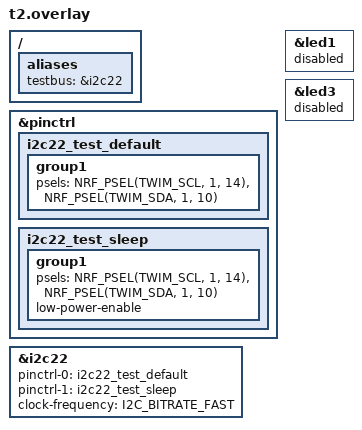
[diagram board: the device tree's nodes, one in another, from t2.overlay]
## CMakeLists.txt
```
cmake_minimum_required(VERSION 3.20.0)

find_package(Zephyr REQUIRED HINTS $ENV{ZEPHYR_BASE})
project(pin_assignment)

target_sources(app PRIVATE src/main.c)
```

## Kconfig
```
config TEST_LABEL
	string "Name of this test case, printed at startup"
	default "T1 baseline — SCL P1.11 (clock pin), SDA P1.10, both on P1"

config TEST_EXPECT_PASS
	bool "This case is expected to communicate successfully"
	default y
	help
	  Set n for the negative controls. The firmware compares the actual
	  result against this and shouts if they disagree — a rule you cannot
	  make fail is a rule you have not tested.

source "Kconfig.zephyr"
```

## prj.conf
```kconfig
CONFIG_I2C=y

# The I2C driver logs its own errors at this level, which is noise on the
# negative controls where errors are the expected result.
CONFIG_I2C_LOG_LEVEL_ERR=y
```

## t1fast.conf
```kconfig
CONFIG_TEST_LABEL="T1-fast — SCL P1.11 (clock pin), SDA P1.10, 1 MHz — control"
CONFIG_TEST_EXPECT_PASS=y
```

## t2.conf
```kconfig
CONFIG_TEST_LABEL="T2 negative — SCL P1.14 (NOT a clock pin), SDA P1.10"
CONFIG_TEST_EXPECT_PASS=n
```

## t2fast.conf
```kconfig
CONFIG_TEST_LABEL="T2-fast — SCL P1.14 (NOT a clock pin), SDA P1.10, 1 MHz"
CONFIG_TEST_EXPECT_PASS=n
```

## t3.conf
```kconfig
CONFIG_TEST_LABEL="T3 negative — SCL P1.11 (P1), SDA P0.04 (P0), ports crossed"
CONFIG_TEST_EXPECT_PASS=n
```

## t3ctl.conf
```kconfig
CONFIG_TEST_LABEL="T3-control — i2c30, SCL P0.03, SDA P0.04, both on P0"
CONFIG_TEST_EXPECT_PASS=y
```

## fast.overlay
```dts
/*
 * Bus speed override — stack on top of another case's overlay:
 *
 *   -DEXTRA_DTC_OVERLAY_FILE="t2.overlay;fast.overlay"
 *
 * 400 kHz leaves so much I2C setup/hold margin that a pin-to-pin skew inside
 * the die does not show. The clock-pin requirement (Table 77, §10.1.2) is a
 * timing-margin claim — the pins are "optimized to ensure correct timing
 * between the clock and data signals" — so it should only bite once the
 * margin is small enough to matter.
 *
 * 1 MHz is the TWIM ceiling on this part; the BME280 is rated to 3.4 MHz, so
 * the sensor is not the limit here.
 */

#include <zephyr/dt-bindings/i2c/i2c.h>

&i2c22 {
	clock-frequency = <I2C_BITRATE_FAST_PLUS>;
};
```

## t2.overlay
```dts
/*
 * T2 — negative control on the clock-pin rule.
 *
 * SCL = P1.14  NOT a clock pin (the QFAA table marks only P1.03, P1.04,
 *              P1.08, P1.11, P1.12 on this port)
 * SDA = P1.10  unchanged from T1
 *
 * Still on P1, so the port rule is satisfied and only the clock-pin rule is
 * violated. That isolation is the point — if this passes, Table 77 does not
 * mean what HARDWARE.md §6 says it means.
 *
 * P1.14 is LED 3, another FET gate behind 1 MΩ. It is used in preference to
 * P1.09 — the pin the original guess actually used — because P1.09 is
 * Button 1 on the DK, and a pressed button shorts SCL to ground, which would
 * produce a failure that proves nothing. To test the historically exact pin
 * instead, swap 14 for 9 below and do not touch Button 1 during the run.
 */

#include <zephyr/dt-bindings/i2c/i2c.h>

&pinctrl {
	i2c22_test_default: i2c22_test_default {
		group1 {
			psels = <NRF_PSEL(TWIM_SCL, 1, 14)>,
				<NRF_PSEL(TWIM_SDA, 1, 10)>;
		};
	};

	i2c22_test_sleep: i2c22_test_sleep {
		group1 {
			psels = <NRF_PSEL(TWIM_SCL, 1, 14)>,
				<NRF_PSEL(TWIM_SDA, 1, 10)>;
			low-power-enable;
		};
	};
};

&i2c22 {
	status = "okay";
	pinctrl-0 = <&i2c22_test_default>;
	pinctrl-1 = <&i2c22_test_sleep>;
	pinctrl-names = "default", "sleep";
	clock-frequency = <I2C_BITRATE_FAST>;
};

&led1 {
	status = "disabled";
};

&led3 {
	status = "disabled";
};

/ {
	aliases {
		testbus = &i2c22;
	};
};
```

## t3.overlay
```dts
/*
 * T3 — negative control on the same-port rule.
 *
 * SCL = P1.11  clock pin, peripheral domain
 * SDA = P0.04  clock pin, LOW-POWER domain
 *
 * Both pins are clock pins, so the only rule violated is the port crossing:
 * §8.8.3 says peripherals must use pins in their own domain and "cannot mix
 * pins from different ports". i2c22 is a peripheral-domain instance (TWIM20-22
 * live there; TWIM30 is the low-power-domain instance that owns P0), so P0.04
 * is out of its reach.
 *
 * P0.04 is Button 3 — chosen over P0.02 because P0.00-P0.03 are claimed by
 * uart30, which the board DTS enables. (The Zephyr console is uart20 on
 * P1.04/P1.05, not the P0 UART.) Do not press Button 3 during the run.
 *
 * i2c22 rather than i2c20: UARTE20 and TWIM20 are the same peripheral
 * instance, and uart20 is the console.
 *
 * This builds clean under NCS v3.2.2 — neither dtc nor the pinctrl layer
 * rejects the port crossing. Whatever enforces §8.8.3 does so in silicon, so
 * this is a runtime test.
 */

#include <zephyr/dt-bindings/i2c/i2c.h>

&pinctrl {
	i2c22_test_default: i2c22_test_default {
		group1 {
			psels = <NRF_PSEL(TWIM_SCL, 1, 11)>,
				<NRF_PSEL(TWIM_SDA, 0, 4)>;
		};
	};

	i2c22_test_sleep: i2c22_test_sleep {
		group1 {
			psels = <NRF_PSEL(TWIM_SCL, 1, 11)>,
				<NRF_PSEL(TWIM_SDA, 0, 4)>;
			low-power-enable;
		};
	};
};

&i2c22 {
	status = "okay";
	pinctrl-0 = <&i2c22_test_default>;
	pinctrl-1 = <&i2c22_test_sleep>;
	pinctrl-names = "default", "sleep";
	clock-frequency = <I2C_BITRATE_FAST>;
};

&button3 {
	status = "disabled";
};

/ {
	aliases {
		testbus = &i2c22;
	};
};
```

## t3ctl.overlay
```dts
/*
 * T3-control — the same P0.04 wire, on the instance that can actually reach it.
 *
 * SCL = P0.03  clock pin, low-power domain
 * SDA = P0.04  unchanged from T3
 *
 * T3 fails with -ENODEV, which is also exactly what a loose jumper looks like.
 * This run keeps SDA physically where T3 had it and moves the peripheral into
 * the same domain as the pin: i2c30 is the low-power-domain TWIM instance,
 * where TWIM20-22 are peripheral-domain. If this passes, the P0.04 wire and
 * the sensor are both good and T3's failure is the port crossing rather than
 * the bench.
 *
 * uart30 has to go: UARTE30 and TWIM30 are the same peripheral instance, and
 * the board DTS enables uart30 on P0.00-P0.03. It is not the console (uart20
 * is), so nothing is lost by disabling it.
 */

#include <zephyr/dt-bindings/i2c/i2c.h>

&uart30 {
	status = "disabled";
};

&pinctrl {
	i2c30_test_default: i2c30_test_default {
		group1 {
			psels = <NRF_PSEL(TWIM_SCL, 0, 3)>,
				<NRF_PSEL(TWIM_SDA, 0, 4)>;
		};
	};

	i2c30_test_sleep: i2c30_test_sleep {
		group1 {
			psels = <NRF_PSEL(TWIM_SCL, 0, 3)>,
				<NRF_PSEL(TWIM_SDA, 0, 4)>;
			low-power-enable;
		};
	};
};

&i2c30 {
	status = "okay";
	pinctrl-0 = <&i2c30_test_default>;
	pinctrl-1 = <&i2c30_test_sleep>;
	pinctrl-names = "default", "sleep";
	clock-frequency = <I2C_BITRATE_FAST>;
};

&button3 {
	status = "disabled";
};

/ {
	aliases {
		testbus = &i2c30;
	};
};
```

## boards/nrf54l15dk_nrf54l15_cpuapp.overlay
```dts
/*
 * T1 — baseline. Our actual pins, both on P1, SCL on a dedicated clock pin.
 *
 * SCL = P1.11  clock pin per the QFAA pin assignment table
 * SDA = P1.10  adjacent, same port, not a clock pin (Table 77 does not
 *              require one for SDA)
 *
 * P1.10 is LED 1 on the DK, but the LED is driven through an NX138AKS FET
 * gate behind 1 MΩ (DK guide Figure 10), so it does not load the bus. The
 * node is disabled here anyway to stop the LED driver claiming the pin.
 *
 * No bias-pull-up: the board uses external 4.7 kΩ (HARDWARE.md §5) and that
 * is the design point being tested. Fit external resistors, or accept your
 * breakout's own. See firmware/README.md.
 */

#include <zephyr/dt-bindings/i2c/i2c.h>

&pinctrl {
	i2c22_test_default: i2c22_test_default {
		group1 {
			psels = <NRF_PSEL(TWIM_SCL, 1, 11)>,
				<NRF_PSEL(TWIM_SDA, 1, 10)>;
		};
	};

	i2c22_test_sleep: i2c22_test_sleep {
		group1 {
			psels = <NRF_PSEL(TWIM_SCL, 1, 11)>,
				<NRF_PSEL(TWIM_SDA, 1, 10)>;
			low-power-enable;
		};
	};
};

&i2c22 {
	status = "okay";
	pinctrl-0 = <&i2c22_test_default>;
	pinctrl-1 = <&i2c22_test_sleep>;
	pinctrl-names = "default", "sleep";
	clock-frequency = <I2C_BITRATE_FAST>;	/* 400 kHz — the rate the
						 * 4.7 kΩ choice was sized for */
};

&led1 {
	status = "disabled";
};

/ {
	aliases {
		testbus = &i2c22;
	};
};
```

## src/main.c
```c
/*
 * Pin-assignment fire-test — nRF54L15 DK (PCA10156).
 *
 * Proves or refutes the datasheet readings that set the I2C pinout in
 * HARDWARE.md §6. One build is one test case; the case is named and its
 * expected outcome declared in Kconfig, so an unexpected result is reported
 * as such rather than left for the operator to notice.
 *
 * The bus is driven raw rather than through the bme280 sensor driver. A
 * driver that retries would hide a marginal bus, and what is under test is the
 * pin assignment, not the sensor.
 *
 * Integrity checking: the BME280 has no CRC on its I2C transfers, so a
 * corrupt byte is indistinguishable from a real one at the protocol level.
 * Instead each pass re-reads the 26-byte factory calibration block and
 * compares it against the copy read at startup. That block is constant for
 * the life of the part, so any difference is the bus, not the sensor — and 26
 * bytes of known-good data catches far more than a single register would.
 */

#include <stdlib.h>
#include <string.h>

#include <zephyr/kernel.h>
#include <zephyr/device.h>
#include <zephyr/drivers/i2c.h>
#include <zephyr/sys/printk.h>

/* Breakouts differ: SDO low is 0x76, SDO high is 0x77. Probe both. */
static const uint8_t candidate_addr[] = { 0x76, 0x77 };

#define REG_CALIB	0x88	/* calib00..25, 26 bytes, constant */
#define REG_ID		0xD0
#define REG_RESET	0xE0
#define REG_CTRL_HUM	0xF2
#define REG_STATUS	0xF3
#define REG_CTRL_MEAS	0xF4
#define REG_TEMP	0xFA	/* 20-bit, 3 bytes */

#define CALIB_LEN	26

#define ID_BME280	0x60
#define ID_BMP280	0x58	/* many "BME280" boards are really this */

/* osrs_t x1, osrs_p x1, forced mode */
#define CTRL_MEAS_FORCED 0x25

/* Enough passes to catch a bus that works once and then does not. A pin that
 * violates the clock-pin rule may well enumerate and fail intermittently. */
#define PASSES		20

static const struct device *const bus = DEVICE_DT_GET(DT_ALIAS(testbus));

static uint8_t addr;
static uint8_t calib_ref[CALIB_LEN];
static uint16_t dig_T1;
static int16_t dig_T2, dig_T3;

static int reg_read(uint8_t reg, uint8_t *buf, size_t len)
{
	return i2c_write_read(bus, addr, &reg, 1, buf, len);
}

static int reg_write(uint8_t reg, uint8_t val)
{
	uint8_t buf[2] = { reg, val };

	return i2c_write(bus, buf, sizeof(buf), addr);
}

/* Bosch's integer compensation, temperature only (BME280 datasheet §4.2.3).
 * Returns hundredths of a degree C. */
static int32_t compensate_temp(int32_t adc_T)
{
	int32_t var1, var2;

	var1 = (((adc_T >> 3) - ((int32_t)dig_T1 << 1)) * (int32_t)dig_T2) >> 11;
	var2 = ((((adc_T >> 4) - (int32_t)dig_T1) *
		 ((adc_T >> 4) - (int32_t)dig_T1)) >> 12) * (int32_t)dig_T3 >> 14;

	return ((var1 + var2) * 5 + 128) >> 8;
}

/* Returns the chip ID, or a negative error. */
static int probe(void)
{
	uint8_t id;
	int err;

	for (size_t i = 0; i < ARRAY_SIZE(candidate_addr); i++) {
		addr = candidate_addr[i];

		err = reg_read(REG_ID, &id, 1);
		if (err == 0 && (id == ID_BME280 || id == ID_BMP280)) {
			return id;
		}
	}

	addr = 0;
	return -ENODEV;
}

/* One measurement cycle plus an integrity check. Exercises writes as well as
 * reads, so a pin that only fails in one direction still shows up. */
static int one_pass(int32_t *temp_centi, bool *integrity_ok)
{
	uint8_t calib[CALIB_LEN];
	uint8_t raw[3];
	int32_t adc_T;
	int err;

	/* ctrl_hum must be written before ctrl_meas or it does not latch. */
	err = reg_write(REG_CTRL_HUM, 0x01);
	if (err) {
		return err;
	}

	err = reg_write(REG_CTRL_MEAS, CTRL_MEAS_FORCED);
	if (err) {
		return err;
	}

	k_msleep(10);

	err = reg_read(REG_CALIB, calib, sizeof(calib));
	if (err) {
		return err;
	}

	*integrity_ok = (memcmp(calib, calib_ref, CALIB_LEN) == 0);

	err = reg_read(REG_TEMP, raw, sizeof(raw));
	if (err) {
		return err;
	}

	adc_T = ((int32_t)raw[0] << 12) | ((int32_t)raw[1] << 4) | (raw[2] >> 4);
	if (adc_T == 0x80000) {
		/* Reset value — the conversion never ran. */
		return -ENODATA;
	}

	*temp_centi = compensate_temp(adc_T);

	return 0;
}

int main(void)
{
	int ok = 0, bus_err = 0, corrupt = 0;
	int32_t temp_centi = 0;
	bool integrity_ok;
	int id, err;

	printk("\n=== %s ===\n", CONFIG_TEST_LABEL);
	printk("expecting: %s\n", IS_ENABLED(CONFIG_TEST_EXPECT_PASS) ? "PASS" : "FAIL");
	printk("bus:       %s\n", bus->name);

	if (!device_is_ready(bus)) {
		printk("bus not ready — the instance failed to initialise.\n");
		printk("VERDICT: FAIL (no bus)%s\n",
		       IS_ENABLED(CONFIG_TEST_EXPECT_PASS) ? "  *** UNEXPECTED ***" : "");
		return 0;
	}

	id = probe();
	if (id < 0) {
		printk("no BME280/BMP280 at 0x76 or 0x77 (%d)\n", id);
		printk("VERDICT: FAIL (no device)%s\n",
		       IS_ENABLED(CONFIG_TEST_EXPECT_PASS)
			       ? "  *** UNEXPECTED — check wiring before trusting this ***" : "");
		return 0;
	}

	printk("found 0x%02x at 0x%02x (%s)\n", id, addr,
	       (id == ID_BME280) ? "BME280" : "BMP280, no humidity");

	err = reg_read(REG_CALIB, calib_ref, sizeof(calib_ref));
	if (err) {
		printk("calibration read failed (%d) — cannot establish a reference\n", err);
		return 0;
	}

	dig_T1 = (uint16_t)(calib_ref[0] | (calib_ref[1] << 8));
	dig_T2 = (int16_t)(calib_ref[2] | (calib_ref[3] << 8));
	dig_T3 = (int16_t)(calib_ref[4] | (calib_ref[5] << 8));

	printk("calibration reference: T1=%u T2=%d T3=%d\n", dig_T1, dig_T2, dig_T3);

	for (int i = 0; i < PASSES; i++) {
		integrity_ok = false;

		err = one_pass(&temp_centi, &integrity_ok);
		if (err) {
			bus_err++;
		} else if (!integrity_ok) {
			corrupt++;
		} else {
			ok++;
		}

		k_msleep(20);
	}

	if (ok > 0) {
		/* Report the last conversion so the operator can sanity check
		 * it against the room, not just trust a counter. */
		printk("last reading: %d.%02d C\n",
		       temp_centi / 100, abs(temp_centi % 100));
	}

	printk("result: %d/%d ok  (%d bus errors, %d calibration mismatches)\n",
	       ok, PASSES, bus_err, corrupt);

	/* A partial pass is a fail. An intermittent bus is exactly what a
	 * violated timing rule looks like, and it is not a result we can
	 * design against. */
	bool passed = (ok == PASSES);

	printk("VERDICT: %s%s\n",
	       passed ? "PASS" : "FAIL",
	       (passed == IS_ENABLED(CONFIG_TEST_EXPECT_PASS))
		       ? "" : "  *** UNEXPECTED — disagrees with HARDWARE.md §6 ***");

	if (passed != IS_ENABLED(CONFIG_TEST_EXPECT_PASS)) {
		/* The first version of this said the datasheet reading was
		 * wrong. It cannot show that. Table 77 is a timing-margin
		 * claim, and a pass only means the margin was not consumed
		 * here — at this rate, this temperature, this bus length. */
		printk("A negative control that passes does not void the rule. It shows\n"
		       "the rule was not reproducible at this operating point, which is\n"
		       "a much weaker statement. See firmware/README.md before moving\n"
		       "any pin on the strength of it.\n");
	}

	return 0;
}
```
